# ATSAMG55J19 register map
Vendor: Microchip Technology; Series: SAMG55; File version: 0
Microchip ATSAMG55J19 Microcontroller
CPU: CM4 r0p1, little endian, MPU, FPU, 4 interrupt priority bits, 50 interrupts
Registers are 32-bit, read-write, reset 0x0 unless marked. A register's access mark holds for its fields unless they carry their own. Offsets are from the block's base; lines under a group give offsets from that group; [hi:lo] are bit positions; {n}, {i} and the like mark numbered series; 'fields as' and 'values as' point back to an identical list; <NAME> marks a mode.

## Memory map
0x00000000 LOCKBIT size 0x8
0x20400000 UHP size 0x5C — USB Host Port
0x40000000 I2SC0 size 0x228 — Inter-IC Sound Controller
0x40004000 I2SC1 size 0x228
0x40008000 FLEXCOM5 size 0x24
0x40008200 USART5 size 0x128
0x40008400 SPI5 size 0x128
0x40008600 TWI5 size 0x128
0x4000C000 FLEXCOM0 size 0x24 — Flexible Serial Communication
0x4000C200 USART0 size 0x128 — Universal Synchronous Asynchronous Receiver Transmitter
0x4000C400 SPI0 size 0x128 — Serial Peripheral Interface
0x4000C600 TWI0 size 0x128 — Two-wire Interface
0x40010000 TC0 size 0x128 — Timer Counter
0x40014000 TC1 size 0x128
0x40018000 FLEXCOM3 size 0x24
0x40018200 USART3 size 0x128
0x40018400 SPI3 size 0x128
0x40018600 TWI3 size 0x128
0x4001C000 FLEXCOM4 size 0x24
0x4001C200 USART4 size 0x128
0x4001C400 SPI4 size 0x128
0x4001C600 TWI4 size 0x128
0x40020000 FLEXCOM1 size 0x24
0x40020200 USART1 size 0x128
0x40020400 SPI1 size 0x128
0x40020600 TWI1 size 0x128
0x40024000 FLEXCOM2 size 0x24
0x40024200 USART2 size 0x128
0x40024400 SPI2 size 0x128
0x40024600 TWI2 size 0x128
0x40028000 MEM2MEM size 0x128 — Memory to Memory
0x4002C000 PDMIC0 size 0x128 — Pulse Density Modulation Interface Controller
0x40030000 PDMIC1 size 0x128
0x40034000 FLEXCOM7 size 0x24
0x40034200 USART7 size 0x128
0x40034400 SPI7 size 0x128
0x40034600 TWI7 size 0x128
0x40038000 ADC size 0x128 — Analog-to-Digital Converter
0x4003C000 CMCC size 0x38 — Cortex-M Cache Controller
0x40040000 FLEXCOM6 size 0x24
0x40040200 USART6 size 0x128
0x40040400 SPI6 size 0x128
0x40040600 TWI6 size 0x128
0x40044000 UDP size 0x78 — USB Device Port
0x40048000 CRCCU size 0x50 — Cyclic Redundancy Check Calculation Unit
0x400E0200 MATRIX size 0x1EC — AHB Bus Matrix
0x400E0400 PMC size 0x134 — Power Management Controller
0x400E0740 CHIPID size 0x8 — Chip Identifier
0x400E0A00 EFC size 0xE8 — Embedded Flash Controller
0x400E0E00 PIOA size 0x114 — Parallel Input/Output Controller
0x400E1000 PIOB size 0x114
0x400E1400 RSTC size 0xC — Reset Controller
0x400E1410 SUPC size 0x20 — Supply Controller
0x400E1430 RTT size 0x14 — Real-time Timer
0x400E1450 WDT size 0xC — Watchdog Timer
0x400E1460 RTC size 0xE8 — Real-time Clock
0x400E1490 GPBR size 0x20 — General Purpose Backup Registers
0xE000E000 SystemControl size 0xD40 — System Control Registers
0xE000E010 SysTick size 0x10 — System timer
0xE000E100 NVIC size 0xE04 — Nested Vectored Interrupt Controller
0xE000ED90 MPU size 0x14 — Memory Protection Unit Registers

## Interrupts
0 SUPC — Supply Controller
1 RSTC — Reset Controller
2 RTC — Real Time Clock
3 RTT — Real Time Timer
4 WDT — Watchdog Timer
5 PMC — Power Management Controller
6 EFC — Enhanced Flash Controller
7 FLEXCOM7
8 FLEXCOM0
9 FLEXCOM1
11 PIOA — Parallel I/O Controller A
12 PIOB — Parallel I/O Controller B
13 PDMIC0 — PDM 0
14 FLEXCOM2
15 MEM2MEM
16 I2SC0
17 I2SC1
18 PDMIC1 — PDM 1
19 FLEXCOM3
20 FLEXCOM4
21 FLEXCOM5
22 FLEXCOM6
23 TC0 — Timer/Counter 0
24 TC1 (TC0) — Timer/Counter 1
25 TC2 (TC0) — Timer/Counter 2
26 TC3 (TC1) — Timer/Counter 3
27 TC4 (TC1) — Timer/Counter 4
28 TC5 (TC1) — Timer/Counter 5
29 ADC — Analog To Digital Converter
47 UHP — USB OHCI
48 UDP — USB Device FS
49 CRCCU

## CHIPID — Chip Identifier
Base 0x400E0740
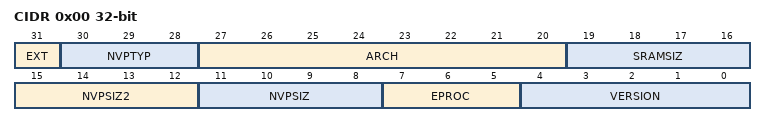
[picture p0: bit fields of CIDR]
0x00 CIDR ro — Chip ID Register
  [31] EXT — Extension Flag
  [30:28] NVPTYP — Nonvolatile Program Memory Type
    0=ROM; 1=ROMLESS (ROMless or on-chip Flash); 2=FLASH (Embedded Flash Memory); 3=ROM_FLASH (ROM and Embedded Flash Memory- NVPSIZ is ROM size- NVPSIZ2 is Flash size); 4=SRAM (SRAM emulating ROM)
  [27:20] ARCH — Architecture Identifier
    68=SAMG55 (SAM G55 (49-lead version))
  [19:16] SRAMSIZ — Internal SRAM Size
    0=_48K (48 Kbytes); 1=_192K (192 Kbytes); 2=_384K (384 Kbytes); 3=_6K (6 Kbytes); 4=_24K (24 Kbytes); 5=_4K (4 Kbytes); 6=_80K (80 Kbytes); 7=_160K (160 Kbytes); 8=_8K (8 Kbytes); 9=_16K (16 Kbytes); 10=_32K (32 Kbytes); 11=_64K (64 Kbytes); 12=_128K (128 Kbytes); 13=_256K (256 Kbytes); 14=_96K (96 Kbytes); 15=_512K (512 Kbytes)
  [15:12] NVPSIZ2 — Second Nonvolatile Program Memory Size
    0=NONE; 1=_8K (8 Kbytes); 2=_16K (16 Kbytes); 3=_32K (32 Kbytes); 5=_64K (64 Kbytes); 7=_128K (128 Kbytes); 9=_256K (256 Kbytes); 10=_512K (512 Kbytes); 12=_1024K (1024 Kbytes); 14=_2048K (2048 Kbytes)
  [11:8] NVPSIZ — Nonvolatile Program Memory Size
    0=NONE; 1=_8K (8 Kbytes); 2=_16K (16 Kbytes); 3=_32K (32 Kbytes); 5=_64K (64 Kbytes); 7=_128K (128 Kbytes); 8=_160K (160 Kbytes); 9=_256K (256 Kbytes); 10=_512K (512 Kbytes); 12=_1024K (1024 Kbytes); 14=_2048K (2048 Kbytes)
  [7:5] EPROC — Embedded Processor
    1=ARM946ES; 2=ARM7TDMI; 3=CM3 (Cortex-M3); 4=ARM920T; 5=ARM926EJS; 6=CA5 (Cortex-A5); 7=CM4 (Cortex-M4)
  [4:0] VERSION — Version of the Device
0x04 EXID ro — Chip ID Extension Register
  [31:0] EXID — Chip ID Extension

## Notices in the file
Copyright (c) 2023 Microchip Technology Inc.
SPDX-License-Identifier: Apache-2.0
Licensed under the Apache License, Version 2.0 (the "License");
you may not use this file except in compliance with the License.
You may obtain a copy of the License at
http://www.apache.org/licenses/LICENSE-2.0
Unless required by applicable law or agreed to in writing, software
distributed under the License is distributed on an "AS IS" BASIS,
WITHOUT WARRANTIES OR CONDITIONS OF ANY KIND, either express or implied.
See the License for the specific language governing permissions and
limitations under the License.
